# Template register map
Vendor: VendorName Co.Ltd; Series: SeriesName; File version: 1.2
CPU: CM7 r0p1, little endian, MPU, FPU, 4 interrupt priority bits
Registers are 32-bit, read-write, no defined reset value unless marked. A register's access mark holds for its fields unless they carry their own. Offsets are from the block's base; [hi:lo] are bit positions; {n}, {i} and the like mark numbered series.

## ADCSAFETYCHKCHK1 — Analog-to-Digitial Safety Checker Check 1
Base 0x40038200
Same registers: ADCSAFETYCHKCHK2 0x40038300, ADCSAFETYCHKCHK3 0x40038400, ADCSAFETYCHKCHK4 0x40038500, ADCSAFETYCHKCHK5 0x40038600, ADCSAFETYCHKCHK6 0x40038700, ADCSAFETYCHKCHK7 0x40038800, ADCSAFETYCHKCHK8 0x40038900
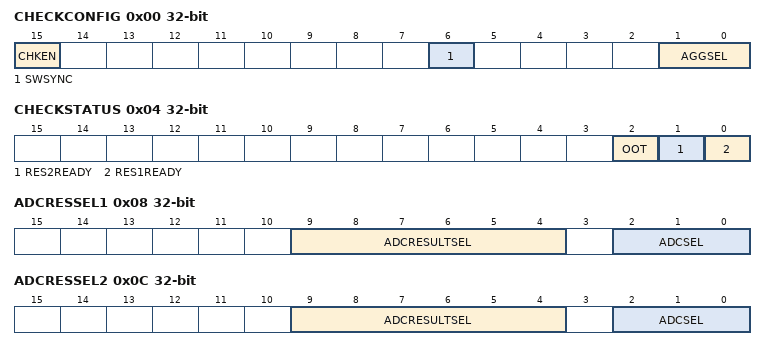
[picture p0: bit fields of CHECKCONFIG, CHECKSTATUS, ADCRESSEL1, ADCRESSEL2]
0x00 CHECKCONFIG — ADCSAFETYCHK_CHK configuration register
  [15] CHKEN — ADCSAFETYCHKCHK CHKEN bit: result checker 1 module enable
  [6] SWSYNC wo — ADCSAFETYCHKCHK SWSYNC bit: write 1 to send a software SYNC event to the result checker 1 module
  [1:0] AGGSEL — ADCSAFETYCHKCHK AGGSEL[1:0] bit: OOT event output selection
0x04 CHECKSTATUS ro — ADCSAFETYCHK_CHK status register
  [2] OOT — ADCSAFETYCHKCHK OOT bit: the difference between CHECKRESULT1 and CHECKRESULT2 out-of-tolerance flag
  [1] RES2READY — ADCSAFETYCHKCHK RES2READY bit: result 2 have readied
  [0] RES1READY — ADCSAFETYCHKCHK RES1READY bit: result 1 have readied
0x08 ADCRESSEL1 — ADCSAFETYCHK_CHK result1 selection register
  [9:4] ADCRESULTSEL — ADCSAFETYCHKCHK ADCRESULTSEL[5:0] bit: ADC result checker 1 result 1 selection bit
  [2:0] ADCSEL — ADCSAFETYCHKCHK ADCSEL[2:0] bit: ADC result checker 1 result 1's ADC peripheral selection bit
0x0C ADCRESSEL2 — ADCSAFETYCHK_CHK result1 selection register
  [9:4] ADCRESULTSEL — ADCSAFETYCHKCHK ADCRESULTSEL[5:0] bit: ADC result checker 1 result 2 selection bit
  [2:0] ADCSEL — ADCSAFETYCHKCHK ADCSEL[2:0] bit: ADC result checker 1 result 2's ADC peripheral selection bit
0x10 TOLERANCE ro — ADCSAFETYCHK_CHK tolerance register
  [23:0] TOLERANCE — ADCSAFETYCHKCHK TOLERANCE[23:0] bit: the tolerance between CHECKRESULT1 and CHECKRESULT2
0x14 CHECKRESULT1 ro — ADCSAFETYCHK_CHK result1 register
  [23:0] RESULT — ADCSAFETYCHKCHK RESULT[23:0] bit: ADC result safety checker 1 capture result 1
0x18 CHECKRESULT2 ro — ADCSAFETYCHK_CHK result1 register
  [23:0] RESULT — ADCSAFETYCHKCHK RESULT[23:0] bit: ADC result safety checker 1 capture result 2

## AESHASH — Advanced Encryption Standard
Base 0x4008C000
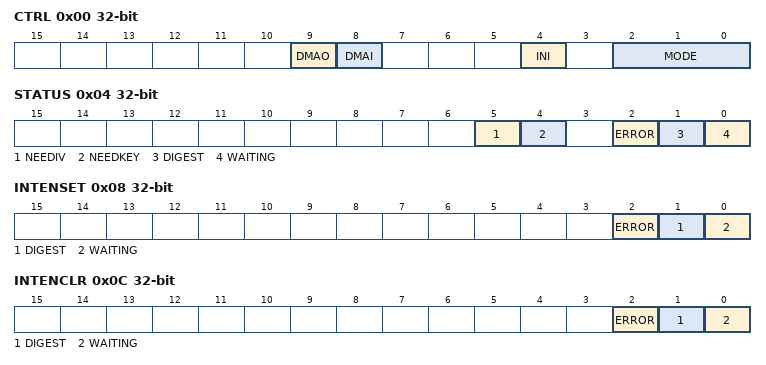
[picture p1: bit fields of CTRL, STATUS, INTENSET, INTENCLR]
0x00 CTRL — AES control register
  [9] DMAO — AESHASH DMAO bit: DMA move out enable
  [8] DMAI — AESHASH DMAI bit: DMA move in enable
  [4] INI — AESHASH INI bit: AES-HASH state machine initialization operation
  [2:0] MODE — AESHASH MODE[2:0] bit: operation mode
0x04 STATUS ro — AES status register
  [5] NEEDIV — AESHASH NEEDIV bit: wait to write the initial vector or nonce
  [4] NEEDKEY — AESHASH NEEDKEY bit: wait to write the key
  [2] ERROR — AESHASH ERROR bit: it is an AHB bus error in the master mode
  [1] DIGEST — AESHASH DIGEST bit: result output ready
  [0] WAITING — AESHASH WAITING bit: waiting to process more data
0x08 INTENSET — AES interrupt enable set register
  [2] ERROR — AESHASH ERROR bit: whether produce error interrupt
  [1] DIGEST — AESHASH DIGEST bit: whether produce interrupt when the output is ready
  [0] WAITING — AESHASH WAITING bit: whether enable interrupt when waiting input data
0x0C INTENCLR — AES interrupt enable clear register
  [2] ERROR — AESHASH ERROR bit: write 1 to clear the ERROR interrupt enabled by INTENSET
  [1] DIGEST — AESHASH DIGEST bit: write 1 to clear the DIGEST interrupt enabled by INTENSET
  [0] WAITING — AESHASH WAITING bit: write 1 to clear the WAITING interrupt enabled by INTENSET
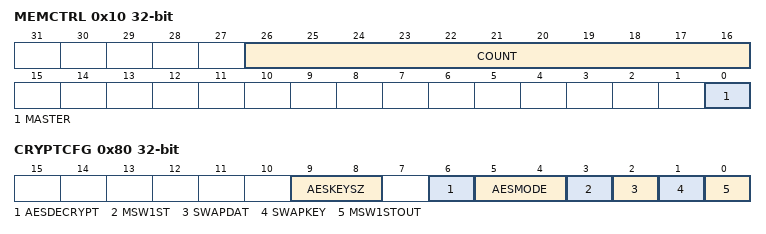
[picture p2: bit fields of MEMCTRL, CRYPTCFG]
0x10 MEMCTRL — AES memory control register
  [26:16] COUNT — AESHASH COUNT[10:0] bit: the number of data blocks copied from MEMADDR to the INDATA register
  [0] MASTER — AESHASH MASTER bit: AES-HASH engine as AHB master enable control
0x14 MEMADDR — AES memory control starting address register
  [31:0] BASE — AESHASH BASE[31:0] bit: the starting base address for copying
0x20 INDATA wo — AES input data register
  [31:0] DATA — AESHASH DATA[31:0] bit: data input register
{0x40+4i} DIGEST{i:02} ro (i=0..7) — AES output register{i}
  [31:0] DIGEST — AESHASH DIGEST[31:0] bit: output data {i}
0x80 CRYPTCFG — AES encryption settings register
  [9:8] AESKEYSZ — AESHASH AESKEYSZ[1:0] bit: AES key length configuration
  [6] AESDECRYPT — AESHASH AESDECRYPT bit: AES encryption and decryption algorithms configuration
  [5:4] AESMODE — AESHASH AESMODE[1:0] bit: AES link mode configuration
  [3] MSW1ST — AESHASH MSW1ST bit: the highest valid character priority loading
  [2] SWAPDAT — AESHASH SWAPDAT bit: swap data
  [1] SWAPKEY — AESHASH SWAPKEY bit: swap key
  [0] MSW1STOUT — AESHASH MSW1STOUT bit: the highest valid character priority output
